# SN32F100 register map
Vendor: SONiX Technology Co., Ltd.; Series: SN32F100; File version: 1.3
CPU: CM0 r0p0, little endian, no MPU, no FPU, 2 interrupt priority bits
Registers are 32-bit, read-write, reset 0x0 unless marked. A register's access mark holds for its fields unless they carry their own. Offsets are from the block's base; [hi:lo] are bit positions; {n}, {i} and the like mark numbered series.

## SN_CT16B0 — 16-bit Timer 0 with Capture function
Base 0x40000000
Same registers: SN_CT16B1 0x40002000
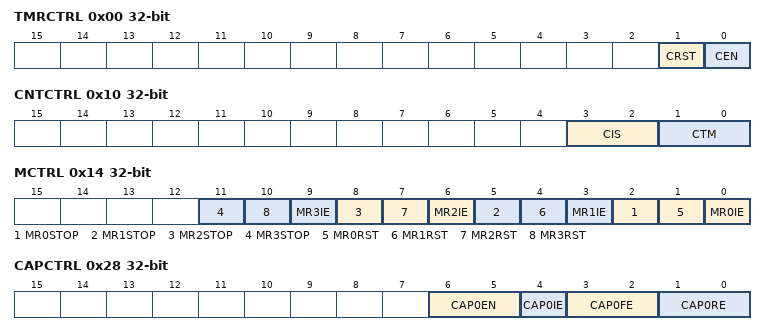
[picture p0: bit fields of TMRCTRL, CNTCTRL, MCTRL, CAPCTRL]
0x00 TMRCTRL — Offset:0x00 CT16Bn Timer Control Register
  [1] CRST — Counter Reset
    0=Disable; 1=Reset Counter (Timer Counter and the Prescale Counter are synchronously reset on the next positive edge of PCLK)
  [0] CEN — Counter enable
    0=Disable counter; 1=Enable Timer Counter and Prescale Counter for counting
0x04 TC — Offset:0x04 CT16Bn Timer Counter Register
  [15:0] TC — Timer Counter
0x08 PRE — Offset:0x08 CT16Bn Prescale Register
  [15:0] PR — Prescaler
0x0C PC — Offset:0x0C CT16Bn Prescale Counter Register
  [15:0] PC — Prescaler Counter
0x10 CNTCTRL — Offset:0x10 CT16Bn Counter Control Register
  [3:2] CIS — Counter Input Select
    0=CT16Bn_CAP0
  [1:0] CTM — Counter/Timer Mode
    0=Timer Mode (Every rising PCLK edge); 1=Counter Mode (TC is incremented on rising edges on the CAP0 input selected by CIS bits.); 2=Counter Mode (TC is incremented on falling edges on the CAP0 input selected by CIS bits.); 3=Counter Mode (TC is incremented on both edges on the CAP0 input selected by CIS bits.)
0x14 MCTRL — Offset:0x14 CT16Bn Match Control Register
  [3n+2] MR{n}STOP (n=0..3) — Stop TC and PC and clear CEN bit when MR{n} matches TC
    0=Disable; 1=Enable (Stop TC and PC and clear CEN bit when MR{n} matches TC)
  [3n+1] MR{n}RST (n=0..3) — Enable reset TC when MR{n} matches TC
    0=Disable; 1=Enable (Reset TC when MR{n} matches TC)
  [3n] MR{n}IE (n=0..3) — Enable generating an interrupt when MR{n} matches TC
    0=Disable; 1=Enable (Generating an interrupt when MR{n} matches TC)
{0x18+4i} MR{i} (reset mask 0xFFFF) (i=0..3) — Offset:{0x18+4i} CT16Bn MR{i} Register
0x28 CAPCTRL — Offset:0x28 CT16Bn Capture Control Register
  [6:5] CAP0EN — CAP0 function enable
    0=Disable; 1=Enable CAP0 function for external Capture pin
  [4] CAP0IE — Interrupt on CT16Bn_CAP0 signal event: a CAP0 load due to a CT16Bn_CAP0 signal event will generate an interrupt.
    0=Disable; 1=Enable (A CAP0 load due to a CT16Bn_CAP0 event will generate an interrupt.)
  [3:2] CAP0FE — Capture/Reset on CT16Bn_CAP0 signal falling edge
    0=Disable; 1=Enable (A sequence of 1 then 0 on CT16Bn_CAP0 will cause CAP0 to be loaded with the contents of TC.); 2=Enable (A sequence of 1 then 0 on CT16Bn_CAP0 signal will reset the TC.)
  [1:0] CAP0RE — Capture/Reset on CT16Bn_CAP0 signal rising edge
    0=Disable; 1=Enable (A sequence of 0 then 1 on CT16Bn_CAP0 will cause CAP0 to be loaded with the contents of TC.); 2=Enable (A sequence of 0 then 1 on CT16Bn_CAP0 signal will reset the TC.)
0x2C CAP0 ro — Offset:0x2C CT16Bn CAP0 Register
  [15:0] CAP0 — Timer counter capture value
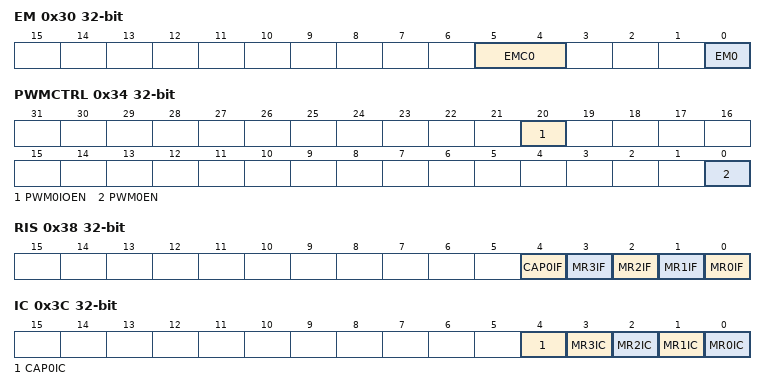
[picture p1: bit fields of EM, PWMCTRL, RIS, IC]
0x30 EM — Offset:0x30 CT16Bn External Match Register
  [5:4] EMC0 — CT16Bn_PWM0 functionality
    0=Do Nothing; 1=Low (CT16Bn_PWM0 pin is LOW); 2=High (CT16Bn_PWM0 pin is HIGH); 3=Toggle CT16Bn_PWM0 pin
  [0] EM0 — When the TC matches MR0, this bit will act according to EMC0[1:0], and also drive the state of CT16Bn_PWM0 output.
0x34 PWMCTRL — Offset:0x34 CT16Bn PWM Control Register
  [20] PWM0IOEN — CT16Bn_PWM0/GPIO selection
    0=Disable (CT16Bn_PWM0 pin is act as GPIO); 1=Enable (CT16Bn_PWM0 pin act as match output, and output depends on PWM0EN bit)
  [0] PWM0EN — PWM0 enable
    0=Disable (CT16Bn_PWM0 is controlled by EM0); 1=Enable PWM mode for CT16Bn_PWM0
0x38 RIS ro — Offset:0x38 CT16Bn Raw Interrupt Status Register
  [4] CAP0IF — Capture channel 0 interrupt flag
    0=No (No interrupt on CAP0); 1=Met interrupt requirements (Interrupt requirements met on CAP0)
  [3] MR3IF — Match channel 3 interrupt flag
    0=No (No interrupt on match channel 3); 1=Met interrupt requirements (Interrupt requirements met on match channel 3)
  [2] MR2IF — Match channel 2 interrupt flag
    0=No (No interrupt on match channel 2); 1=Met interrupt requirements (Interrupt requirements met on match channel 2)
  [1] MR1IF — Match channel 1 interrupt flag
    0=No (No interrupt on match channel 1); 1=Met interrupt requirements (Interrupt requirements met on match channel 1)
  [0] MR0IF — Match channel 0 interrupt flag
    0=No interrupt on match channel 0; 1=Met interrupt requirements (Interrupt requirements met on match channel 0)
0x3C IC wo — Offset:0x3C CT16Bn Interrupt Clear Register
  [4] CAP0IC — CAP0IF clear bit
    0=No effect; 1=Clear CAP0IF
  [n] MR{n}IC (n=0..3) — MR{n}IF clear bit
    0=No effect; 1=Clear MR{n}IF
